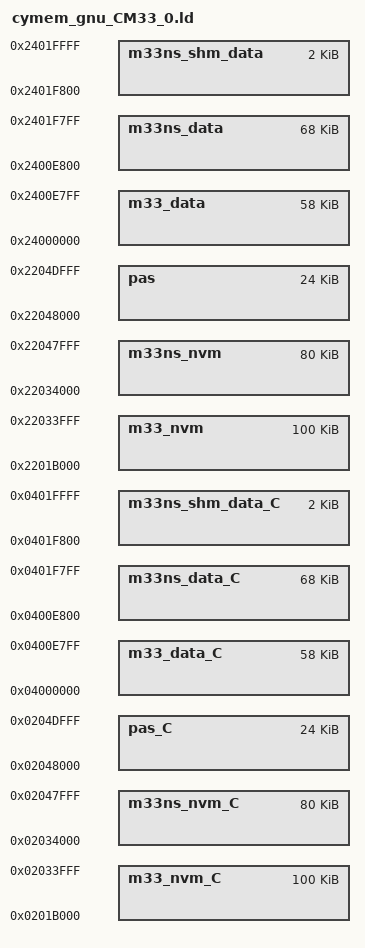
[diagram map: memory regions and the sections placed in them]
/* This file is automatically generated. */

CYMEM_CM33_0_m33_nvm_START = 0x2201B000;
CYMEM_CM33_0_m33_nvm_C_START = 0x0201B000;
CYMEM_CM33_0_m33_nvm_SIZE = 0x00019000;
CYMEM_CM33_0_m33_nvm_OFFSET = 0x0001B000;
CYMEM_CM33_0_m33ns_nvm_START = 0x22034000;
CYMEM_CM33_0_m33ns_nvm_C_START = 0x02034000;
CYMEM_CM33_0_m33ns_nvm_SIZE = 0x00014000;
CYMEM_CM33_0_m33ns_nvm_OFFSET = 0x00034000;
CYMEM_CM33_0_pas_START = 0x22048000;
CYMEM_CM33_0_pas_C_START = 0x02048000;
CYMEM_CM33_0_pas_SIZE = 0x00006000;
CYMEM_CM33_0_pas_OFFSET = 0x00048000;
CYMEM_CM33_0_m33_data_START = 0x24000000;
CYMEM_CM33_0_m33_data_C_START = 0x04000000;
CYMEM_CM33_0_m33_data_SIZE = 0x0000E800;
CYMEM_CM33_0_m33_data_OFFSET = 0x00000000;
CYMEM_CM33_0_m33ns_data_START = 0x2400E800;
CYMEM_CM33_0_m33ns_data_C_START = 0x0400E800;
CYMEM_CM33_0_m33ns_data_SIZE = 0x00011000;
CYMEM_CM33_0_m33ns_data_OFFSET = 0x0000E800;
CYMEM_CM33_0_m33ns_shm_data_START = 0x2401F800;
CYMEM_CM33_0_m33ns_shm_data_C_START = 0x0401F800;
CYMEM_CM33_0_m33ns_shm_data_SIZE = 0x00000800;
CYMEM_CM33_0_m33ns_shm_data_OFFSET = 0x0001F800;

MEMORY
{
    m33_nvm : ORIGIN = 0x2201B000, LENGTH = 0x00019000
    m33_nvm_C : ORIGIN = 0x0201B000, LENGTH = 0x00019000
    m33ns_nvm : ORIGIN = 0x22034000, LENGTH = 0x00014000
    m33ns_nvm_C : ORIGIN = 0x02034000, LENGTH = 0x00014000
    pas : ORIGIN = 0x22048000, LENGTH = 0x00006000
    pas_C : ORIGIN = 0x02048000, LENGTH = 0x00006000
    m33_data : ORIGIN = 0x24000000, LENGTH = 0x0000E800
    m33_data_C : ORIGIN = 0x04000000, LENGTH = 0x0000E800
    m33ns_data : ORIGIN = 0x2400E800, LENGTH = 0x00011000
    m33ns_data_C : ORIGIN = 0x0400E800, LENGTH = 0x00011000
    m33ns_shm_data : ORIGIN = 0x2401F800, LENGTH = 0x00000800
    m33ns_shm_data_C : ORIGIN = 0x0401F800, LENGTH = 0x00000800
}

REGION_ALIAS("m33_nvm_sel", m33_nvm_C)
REGION_ALIAS("m33ns_nvm_sel", m33ns_nvm_C)
REGION_ALIAS("pas_sel", pas_C)
REGION_ALIAS("m33_data_sel", m33_data_C)
REGION_ALIAS("m33ns_data_sel", m33ns_data_C)
REGION_ALIAS("m33ns_shm_data_sel", m33ns_shm_data_C)
